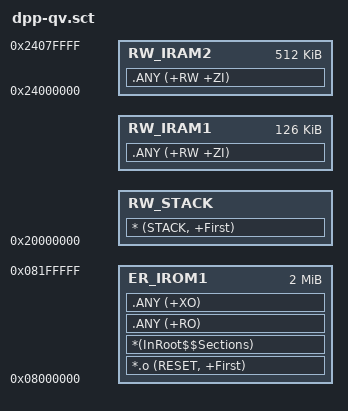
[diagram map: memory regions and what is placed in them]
; *************************************************************
; *** Scatter-Loading Description File generated by uVision ***
;
; Modified by Quantum Leaps:
; added STACK as the first section in RW_STACK
; *************************************************************

LR_IROM1 0x08000000 0x00200000  {    ; load region size_region
  ER_IROM1 0x08000000 0x00200000  {  ; load address = execution address
   *.o (RESET, +First)
   *(InRoot$$Sections)
   .ANY (+RO)
   .ANY (+XO)
  }

  RW_STACK 0x20000000 {              ; <== Quantum Leaps 
   * (STACK, +First)
  }
  RW_IRAM1 +0 (0x00020000 - 2048) {  ; NOTE: 2048 assumed for STACK size!
   .ANY (+RW +ZI)
  }
  RW_IRAM2 0x24000000 0x00080000  {
   .ANY (+RW +ZI)
  }
}

